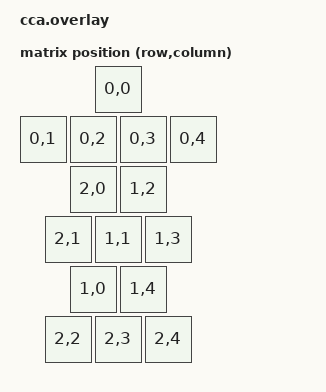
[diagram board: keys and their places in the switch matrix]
// This file was generated from a template. Edit it to match your keyboard.
// See https://zmk.dev/docs/development/hardware-integration/new-shield for more
// instructions.

#include <dt-bindings/zmk/matrix_transform.h>

#include "cca-layouts.dtsi"

/ {
    chosen {
        zmk,physical-layout = &default_layout;
    };

    // Matrix pins are board specific: see boards/<board>.overlay.
    kscan: kscan {
        compatible = "zmk,kscan-gpio-matrix";
        diode-direction = "col2row";
        wakeup-source;
    };

    // ScreenKey displays are board specific: see boards/<board>.overlay.
    // Their switches are the F1-F4 keys, RC(0, 1) to RC(0, 4).
    screenkeys: screenkeys {
        compatible = "cca,screenkeys";

        screenkey_0 {
            display = <&screenkey_lcd0>;
            key-position = <1>;
        };

        screenkey_1 {
            display = <&screenkey_lcd1>;
            key-position = <2>;
        };

        screenkey_2 {
            display = <&screenkey_lcd2>;
            key-position = <3>;
        };

        screenkey_3 {
            display = <&screenkey_lcd3>;
            key-position = <4>;
        };
    };

    default_transform: default_transform {
        compatible = "zmk,matrix-transform";
        columns = <5>;
        rows = <3>;

        map = <
            RC(0, 0)
            RC(0, 1) RC(0, 2) RC(0, 3) RC(0, 4)
                         RC(2, 0) RC(1, 2)
                     RC(2, 1) RC(1, 1) RC(1, 3)
                         RC(1, 0) RC(1, 4)
              RC(2, 2) RC(2, 3) RC(2, 4)
        >;
    };
};
